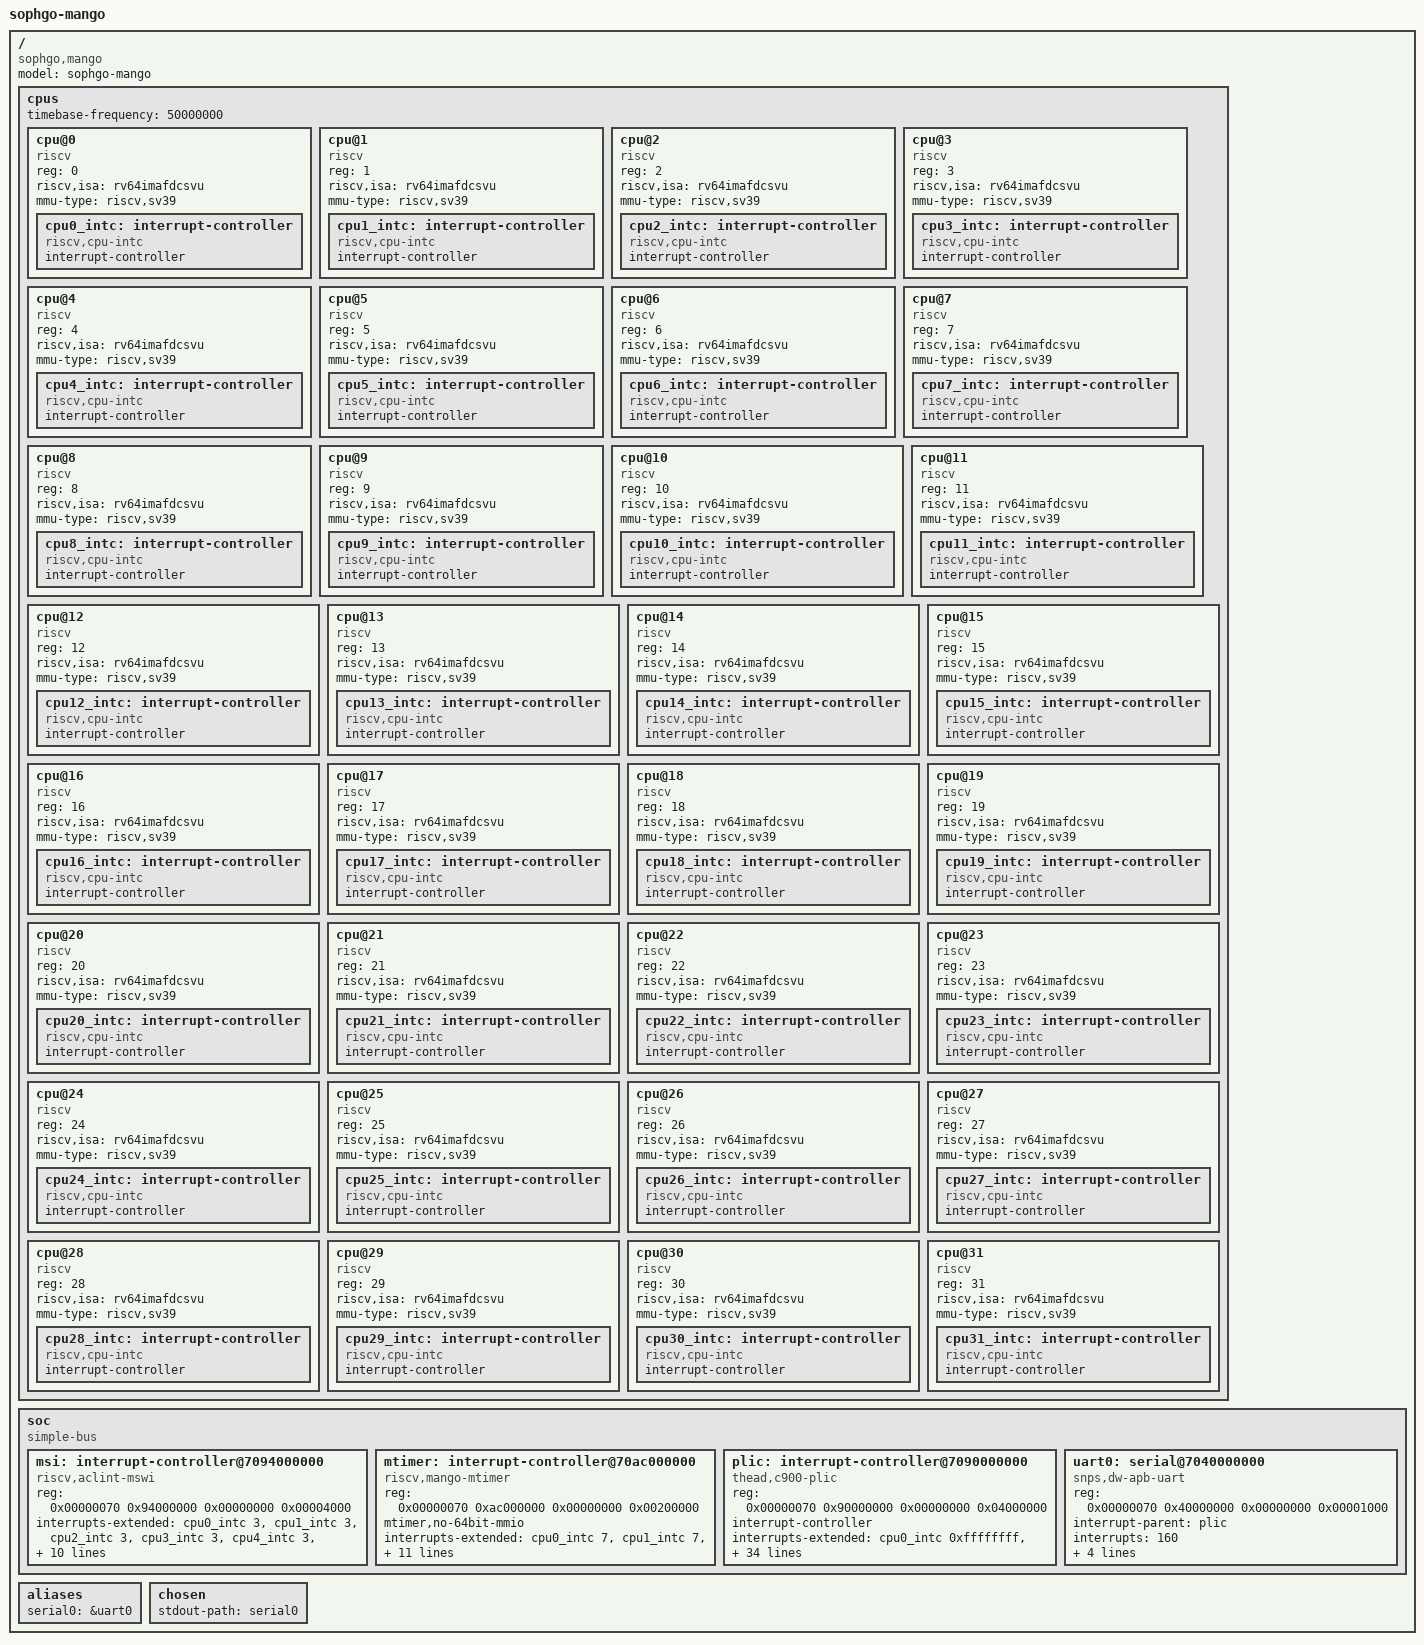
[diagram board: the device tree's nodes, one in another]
/dts-v1/;
/ {
	#address-cells = <2>;
	#size-cells = <2>;
	model = "sophgo-mango";
	compatible = "sophgo,mango";

	cpus {
		#address-cells = <1>;
		#size-cells = <0>;
		timebase-frequency = <50000000>;
		cpu@0 {
			device_type = "cpu";
			reg = <0>;
			status = "okay";
			compatible = "riscv";
			riscv,isa = "rv64imafdcsvu";
			mmu-type = "riscv,sv39";
			cpu0_intc: interrupt-controller {
				#interrupt-cells = <1>;
				compatible = "riscv,cpu-intc";
				interrupt-controller;
			};
		};
		cpu@1 {
			device_type = "cpu";
			reg = <1>;
			status = "okay";
			compatible = "riscv";
			riscv,isa = "rv64imafdcsvu";
			mmu-type = "riscv,sv39";
			cpu1_intc: interrupt-controller {
				#interrupt-cells = <1>;
				compatible = "riscv,cpu-intc";
				interrupt-controller;
			};
		};
		cpu@2 {
			device_type = "cpu";
			reg = <2>;
			status = "okay";
			compatible = "riscv";
			riscv,isa = "rv64imafdcsvu";
			mmu-type = "riscv,sv39";
			cpu2_intc: interrupt-controller {
				#interrupt-cells = <1>;
				compatible = "riscv,cpu-intc";
				interrupt-controller;
			};
		};
		cpu@3 {
			device_type = "cpu";
			reg = <3>;
			status = "okay";
			compatible = "riscv";
			riscv,isa = "rv64imafdcsvu";
			mmu-type = "riscv,sv39";
			cpu3_intc: interrupt-controller {
				#interrupt-cells = <1>;
				compatible = "riscv,cpu-intc";
				interrupt-controller;
			};
		};
		cpu@4 {
			device_type = "cpu";
			reg = <4>;
			status = "okay";
			compatible = "riscv";
			riscv,isa = "rv64imafdcsvu";
			mmu-type = "riscv,sv39";
			cpu4_intc: interrupt-controller {
				#interrupt-cells = <1>;
				compatible = "riscv,cpu-intc";
				interrupt-controller;
			};
		};
		cpu@5 {
			device_type = "cpu";
			reg = <5>;
			status = "okay";
			compatible = "riscv";
			riscv,isa = "rv64imafdcsvu";
			mmu-type = "riscv,sv39";
			cpu5_intc: interrupt-controller {
				#interrupt-cells = <1>;
				compatible = "riscv,cpu-intc";
				interrupt-controller;
			};
		};
		cpu@6 {
			device_type = "cpu";
			reg = <6>;
			status = "okay";
			compatible = "riscv";
			riscv,isa = "rv64imafdcsvu";
			mmu-type = "riscv,sv39";
			cpu6_intc: interrupt-controller {
				#interrupt-cells = <1>;
				compatible = "riscv,cpu-intc";
				interrupt-controller;
			};
		};
		cpu@7 {
			device_type = "cpu";
			reg = <7>;
			status = "okay";
			compatible = "riscv";
			riscv,isa = "rv64imafdcsvu";
			mmu-type = "riscv,sv39";
			cpu7_intc: interrupt-controller {
				#interrupt-cells = <1>;
				compatible = "riscv,cpu-intc";
				interrupt-controller;
			};
		};
		cpu@8 {
			device_type = "cpu";
			reg = <8>;
			status = "okay";
			compatible = "riscv";
			riscv,isa = "rv64imafdcsvu";
			mmu-type = "riscv,sv39";
			cpu8_intc: interrupt-controller {
				#interrupt-cells = <1>;
				compatible = "riscv,cpu-intc";
				interrupt-controller;
			};
		};
		cpu@9 {
			device_type = "cpu";
			reg = <9>;
			status = "okay";
			compatible = "riscv";
			riscv,isa = "rv64imafdcsvu";
			mmu-type = "riscv,sv39";
			cpu9_intc: interrupt-controller {
				#interrupt-cells = <1>;
				compatible = "riscv,cpu-intc";
				interrupt-controller;
			};
		};
		cpu@10 {
			device_type = "cpu";
			reg = <10>;
			status = "okay";
			compatible = "riscv";
			riscv,isa = "rv64imafdcsvu";
			mmu-type = "riscv,sv39";
			cpu10_intc: interrupt-controller {
				#interrupt-cells = <1>;
				compatible = "riscv,cpu-intc";
				interrupt-controller;
			};
		};
		cpu@11 {
			device_type = "cpu";
			reg = <11>;
			status = "okay";
			compatible = "riscv";
			riscv,isa = "rv64imafdcsvu";
			mmu-type = "riscv,sv39";
			cpu11_intc: interrupt-controller {
				#interrupt-cells = <1>;
				compatible = "riscv,cpu-intc";
				interrupt-controller;
			};
		};
		cpu@12 {
			device_type = "cpu";
			reg = <12>;
			status = "okay";
			compatible = "riscv";
			riscv,isa = "rv64imafdcsvu";
			mmu-type = "riscv,sv39";
			cpu12_intc: interrupt-controller {
				#interrupt-cells = <1>;
				compatible = "riscv,cpu-intc";
				interrupt-controller;
			};
		};
		cpu@13 {
			device_type = "cpu";
			reg = <13>;
			status = "okay";
			compatible = "riscv";
			riscv,isa = "rv64imafdcsvu";
			mmu-type = "riscv,sv39";
			cpu13_intc: interrupt-controller {
				#interrupt-cells = <1>;
				compatible = "riscv,cpu-intc";
				interrupt-controller;
			};
		};
		cpu@14 {
			device_type = "cpu";
			reg = <14>;
			status = "okay";
			compatible = "riscv";
			riscv,isa = "rv64imafdcsvu";
			mmu-type = "riscv,sv39";
			cpu14_intc: interrupt-controller {
				#interrupt-cells = <1>;
				compatible = "riscv,cpu-intc";
				interrupt-controller;
			};
		};
		cpu@15 {
			device_type = "cpu";
			reg = <15>;
			status = "okay";
			compatible = "riscv";
			riscv,isa = "rv64imafdcsvu";
			mmu-type = "riscv,sv39";
			cpu15_intc: interrupt-controller {
				#interrupt-cells = <1>;
				compatible = "riscv,cpu-intc";
				interrupt-controller;
			};
		};
		cpu@16 {
			device_type = "cpu";
			reg = <16>;
			status = "okay";
			compatible = "riscv";
			riscv,isa = "rv64imafdcsvu";
			mmu-type = "riscv,sv39";
			cpu16_intc: interrupt-controller {
				#interrupt-cells = <1>;
				compatible = "riscv,cpu-intc";
				interrupt-controller;
			};
		};
		cpu@17 {
			device_type = "cpu";
			reg = <17>;
			status = "okay";
			compatible = "riscv";
			riscv,isa = "rv64imafdcsvu";
			mmu-type = "riscv,sv39";
			cpu17_intc: interrupt-controller {
				#interrupt-cells = <1>;
				compatible = "riscv,cpu-intc";
				interrupt-controller;
			};
		};
		cpu@18 {
			device_type = "cpu";
			reg = <18>;
			status = "okay";
			compatible = "riscv";
			riscv,isa = "rv64imafdcsvu";
			mmu-type = "riscv,sv39";
			cpu18_intc: interrupt-controller {
				#interrupt-cells = <1>;
				compatible = "riscv,cpu-intc";
				interrupt-controller;
			};
		};
		cpu@19 {
			device_type = "cpu";
			reg = <19>;
			status = "okay";
			compatible = "riscv";
			riscv,isa = "rv64imafdcsvu";
			mmu-type = "riscv,sv39";
			cpu19_intc: interrupt-controller {
				#interrupt-cells = <1>;
				compatible = "riscv,cpu-intc";
				interrupt-controller;
			};
		};
		cpu@20 {
			device_type = "cpu";
			reg = <20>;
			status = "okay";
			compatible = "riscv";
			riscv,isa = "rv64imafdcsvu";
			mmu-type = "riscv,sv39";
			cpu20_intc: interrupt-controller {
				#interrupt-cells = <1>;
				compatible = "riscv,cpu-intc";
				interrupt-controller;
			};
		};
		cpu@21 {
			device_type = "cpu";
			reg = <21>;
			status = "okay";
			compatible = "riscv";
			riscv,isa = "rv64imafdcsvu";
			mmu-type = "riscv,sv39";
			cpu21_intc: interrupt-controller {
				#interrupt-cells = <1>;
				compatible = "riscv,cpu-intc";
				interrupt-controller;
			};
		};
		cpu@22 {
			device_type = "cpu";
			reg = <22>;
			status = "okay";
			compatible = "riscv";
			riscv,isa = "rv64imafdcsvu";
			mmu-type = "riscv,sv39";
			cpu22_intc: interrupt-controller {
				#interrupt-cells = <1>;
				compatible = "riscv,cpu-intc";
				interrupt-controller;
			};
		};
		cpu@23 {
			device_type = "cpu";
			reg = <23>;
			status = "okay";
			compatible = "riscv";
			riscv,isa = "rv64imafdcsvu";
			mmu-type = "riscv,sv39";
			cpu23_intc: interrupt-controller {
				#interrupt-cells = <1>;
				compatible = "riscv,cpu-intc";
				interrupt-controller;
			};
		};
		cpu@24 {
			device_type = "cpu";
			reg = <24>;
			status = "okay";
			compatible = "riscv";
			riscv,isa = "rv64imafdcsvu";
			mmu-type = "riscv,sv39";
			cpu24_intc: interrupt-controller {
				#interrupt-cells = <1>;
				compatible = "riscv,cpu-intc";
				interrupt-controller;
			};
		};
		cpu@25 {
			device_type = "cpu";
			reg = <25>;
			status = "okay";
			compatible = "riscv";
			riscv,isa = "rv64imafdcsvu";
			mmu-type = "riscv,sv39";
			cpu25_intc: interrupt-controller {
				#interrupt-cells = <1>;
				compatible = "riscv,cpu-intc";
				interrupt-controller;
			};
		};
		cpu@26 {
			device_type = "cpu";
			reg = <26>;
			status = "okay";
			compatible = "riscv";
			riscv,isa = "rv64imafdcsvu";
			mmu-type = "riscv,sv39";
			cpu26_intc: interrupt-controller {
				#interrupt-cells = <1>;
				compatible = "riscv,cpu-intc";
				interrupt-controller;
			};
		};
		cpu@27 {
			device_type = "cpu";
			reg = <27>;
			status = "okay";
			compatible = "riscv";
			riscv,isa = "rv64imafdcsvu";
			mmu-type = "riscv,sv39";
			cpu27_intc: interrupt-controller {
				#interrupt-cells = <1>;
				compatible = "riscv,cpu-intc";
				interrupt-controller;
			};
		};
		cpu@28 {
			device_type = "cpu";
			reg = <28>;
			status = "okay";
			compatible = "riscv";
			riscv,isa = "rv64imafdcsvu";
			mmu-type = "riscv,sv39";
			cpu28_intc: interrupt-controller {
				#interrupt-cells = <1>;
				compatible = "riscv,cpu-intc";
				interrupt-controller;
			};
		};
		cpu@29 {
			device_type = "cpu";
			reg = <29>;
			status = "okay";
			compatible = "riscv";
			riscv,isa = "rv64imafdcsvu";
			mmu-type = "riscv,sv39";
			cpu29_intc: interrupt-controller {
				#interrupt-cells = <1>;
				compatible = "riscv,cpu-intc";
				interrupt-controller;
			};
		};
		cpu@30 {
			device_type = "cpu";
			reg = <30>;
			status = "okay";
			compatible = "riscv";
			riscv,isa = "rv64imafdcsvu";
			mmu-type = "riscv,sv39";
			cpu30_intc: interrupt-controller {
				#interrupt-cells = <1>;
				compatible = "riscv,cpu-intc";
				interrupt-controller;
			};
		};
		cpu@31 {
			device_type = "cpu";
			reg = <31>;
			status = "okay";
			compatible = "riscv";
			riscv,isa = "rv64imafdcsvu";
			mmu-type = "riscv,sv39";
			cpu31_intc: interrupt-controller {
				#interrupt-cells = <1>;
				compatible = "riscv,cpu-intc";
				interrupt-controller;
			};
		};
	};

	soc {
		#address-cells = <2>;
		#size-cells = <2>;
		compatible = "simple-bus";
		ranges;

		msi: interrupt-controller@7094000000 {
			compatible = "riscv,aclint-mswi";
			reg = <0x00000070 0x94000000 0x00000000 0x00004000>;
			interrupts-extended = <
				&cpu0_intc 3
				&cpu1_intc 3
				&cpu2_intc 3
				&cpu3_intc 3
				&cpu4_intc 3
				&cpu5_intc 3
				&cpu6_intc 3
				&cpu7_intc 3
				&cpu8_intc 3
				&cpu9_intc 3
				&cpu10_intc 3
				&cpu11_intc 3
				&cpu12_intc 3
				&cpu13_intc 3
				&cpu14_intc 3
				&cpu15_intc 3
				&cpu16_intc 3
				&cpu17_intc 3
				&cpu18_intc 3
				&cpu19_intc 3
				&cpu20_intc 3
				&cpu21_intc 3
				&cpu22_intc 3
				&cpu23_intc 3
				&cpu24_intc 3
				&cpu25_intc 3
				&cpu26_intc 3
				&cpu27_intc 3
				&cpu28_intc 3
				&cpu29_intc 3
				&cpu30_intc 3
				&cpu31_intc 3
				>;
			interrupt-controller;
			#interrupt-cells = <0>;
		};

		mtimer: interrupt-controller@70ac000000 {
			compatible = "riscv,mango-mtimer";
			reg = <0x00000070 0xac000000 0x00000000 0x00200000>;
			mtimer,no-64bit-mmio;
			interrupts-extended = <
				&cpu0_intc 7
				&cpu1_intc 7
				&cpu2_intc 7
				&cpu3_intc 7
				&cpu4_intc 7
				&cpu5_intc 7
				&cpu6_intc 7
				&cpu7_intc 7
				&cpu8_intc 7
				&cpu9_intc 7
				&cpu10_intc 7
				&cpu11_intc 7
				&cpu12_intc 7
				&cpu13_intc 7
				&cpu14_intc 7
				&cpu15_intc 7
				&cpu16_intc 7
				&cpu17_intc 7
				&cpu18_intc 7
				&cpu19_intc 7
				&cpu20_intc 7
				&cpu21_intc 7
				&cpu22_intc 7
				&cpu23_intc 7
				&cpu24_intc 7
				&cpu25_intc 7
				&cpu26_intc 7
				&cpu27_intc 7
				&cpu28_intc 7
				&cpu29_intc 7
				&cpu30_intc 7
				&cpu31_intc 7
				>;
			interrupt-controller;
			#interrupt-cells = <0>;
		};

		plic: interrupt-controller@7090000000 {
			#interrupt-cells = <1>;
			compatible = "thead,c900-plic";
			reg = <0x00000070 0x90000000 0x00000000 0x04000000>;
			interrupt-controller;
			interrupts-extended = <
				&cpu0_intc  0xffffffff &cpu0_intc  9
				&cpu1_intc  0xffffffff &cpu1_intc  9
				&cpu2_intc  0xffffffff &cpu2_intc  9
				&cpu3_intc  0xffffffff &cpu3_intc  9
				&cpu4_intc  0xffffffff &cpu4_intc  9
				&cpu5_intc  0xffffffff &cpu5_intc  9
				&cpu6_intc  0xffffffff &cpu6_intc  9
				&cpu7_intc  0xffffffff &cpu7_intc  9
				&cpu8_intc  0xffffffff &cpu8_intc  9
				&cpu9_intc  0xffffffff &cpu9_intc  9
				&cpu10_intc  0xffffffff &cpu10_intc  9
				&cpu11_intc  0xffffffff &cpu11_intc  9
				&cpu12_intc  0xffffffff &cpu12_intc  9
				&cpu13_intc  0xffffffff &cpu13_intc  9
				&cpu14_intc  0xffffffff &cpu14_intc  9
				&cpu15_intc  0xffffffff &cpu15_intc  9
				&cpu16_intc  0xffffffff &cpu16_intc  9
				&cpu17_intc  0xffffffff &cpu17_intc  9
				&cpu18_intc  0xffffffff &cpu18_intc  9
				&cpu19_intc  0xffffffff &cpu19_intc  9
				&cpu20_intc  0xffffffff &cpu20_intc  9
				&cpu21_intc  0xffffffff &cpu21_intc  9
				&cpu22_intc  0xffffffff &cpu22_intc  9
				&cpu23_intc  0xffffffff &cpu23_intc  9
				&cpu24_intc  0xffffffff &cpu24_intc  9
				&cpu25_intc  0xffffffff &cpu25_intc  9
				&cpu26_intc  0xffffffff &cpu26_intc  9
				&cpu27_intc  0xffffffff &cpu27_intc  9
				&cpu28_intc  0xffffffff &cpu28_intc  9
				&cpu29_intc  0xffffffff &cpu29_intc  9
				&cpu30_intc  0xffffffff &cpu30_intc  9
				&cpu31_intc  0xffffffff &cpu31_intc  9
				>;
			reg-names = "control";
			riscv,max-priority = <7>;
			riscv,ndev = <179>;
		};

		uart0: serial@7040000000 {
			compatible = "snps,dw-apb-uart";
			reg = <0x00000070 0x40000000 0x00000000 0x00001000>;
			interrupt-parent = <&plic>;
			interrupts = <160>;
			clock-frequency = <153600>;
			current-speed = <9600>;
			reg-shift = <2>;
			reg-io-width = <4>;
		};
	};

	aliases {
		serial0 = &uart0;
	};

	chosen {
		stdout-path = "serial0";
	};
};
